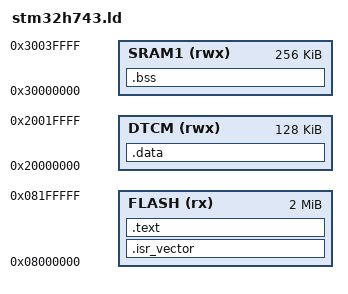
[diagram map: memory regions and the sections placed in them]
/* STM32H743 Linker Script for Renode Simulation */

MEMORY
{
    FLASH  (rx)  : ORIGIN = 0x08000000, LENGTH = 2048K
    DTCM   (rwx) : ORIGIN = 0x20000000, LENGTH = 128K
    SRAM1  (rwx) : ORIGIN = 0x30000000, LENGTH = 256K
}

ENTRY(Reset_Handler)

_estack = ORIGIN(DTCM) + LENGTH(DTCM);

SECTIONS
{
    .isr_vector :
    {
        . = ALIGN(4);
        KEEP(*(.isr_vector))
        . = ALIGN(4);
    } >FLASH

    .text :
    {
        . = ALIGN(4);
        *(.text)
        *(.text*)
        *(.rodata)
        *(.rodata*)
        . = ALIGN(4);
        _etext = .;
    } >FLASH

    _sidata = LOADADDR(.data);

    .data : AT(_etext)
    {
        . = ALIGN(4);
        _sdata = .;
        *(.data)
        *(.data*)
        . = ALIGN(4);
        _edata = .;
    } >DTCM

    .bss :
    {
        . = ALIGN(4);
        _sbss = .;
        *(.bss)
        *(.bss*)
        *(COMMON)
        . = ALIGN(4);
        _ebss = .;
    } >SRAM1
}
